VERSION ""

NS_ :

BS_:

BU_:

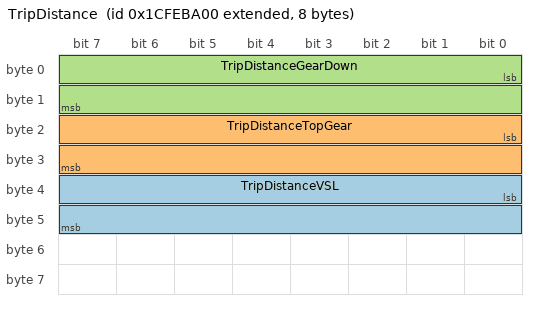
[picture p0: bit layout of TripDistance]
BO_ 2633939456 TripDistance: 8 Vector__XXX
 SG_ TripDistanceVSL : 32|16@1+ (1,0) [0|65535] "Km" Vector__XXX
 SG_ TripDistanceTopGear : 16|16@1+ (1,0) [0|65535] "Km" Vector__XXX
 SG_ TripDistanceGearDown : 0|16@1+ (1,0) [0|65535] "Km" Vector__XXX

BA_DEF_ SG_  "SigType" ENUM  "Default","Range","RangeSigned","ASCII","Discrete","Control","ReferencePGN","DTC","StringDelimiter","StringLength","StringLengthControl";
BA_DEF_ SG_  "GenSigEVName" STRING ;
BA_DEF_ SG_  "GenSigILSupport" ENUM  "Yes","No";
BA_DEF_ SG_  "GenSigSendType" ENUM  "Cyclic","OnWrite","OnWriteWithRepetition","OnChange","OnChangeWithRepetition","IfActive","IfActiveWithRepetition","NoSigSendType";
BA_DEF_ BO_  "GenMsgILSupport" ENUM  "Yes","No";
BA_DEF_ BU_  "NmStationAddress" INT 0 255;
BA_DEF_ BO_  "GenMsgSendType" ENUM  "cyclic","NotUsed","IfActive","NotUsed","NotUsed","NotUsed","NotUsed","NotUsed","noMsgSendType";
BA_DEF_ BO_  "GenMsgRequestable" INT 0 1;
BA_DEF_  "DBName" STRING ;
BA_DEF_  "BusType" STRING ;
BA_DEF_  "ProtocolType" STRING ;
BA_DEF_ BO_  "VFrameFormat" ENUM  "StandardCAN","ExtendedCAN","reserved","J1939PG";
BA_DEF_DEF_  "SigType" "Default";
BA_DEF_DEF_  "GenSigEVName" "Env@Nodename_@Signame";
BA_DEF_DEF_  "GenSigILSupport" "Yes";
BA_DEF_DEF_  "GenSigSendType" "NoSigSendType";
BA_DEF_DEF_  "GenMsgILSupport" "Yes";
BA_DEF_DEF_  "NmStationAddress" 254;
BA_DEF_DEF_  "GenMsgSendType" "noMsgSendType";
BA_DEF_DEF_  "GenMsgRequestable" 1;
BA_DEF_DEF_  "DBName" "";
BA_DEF_DEF_  "BusType" "CAN";
BA_DEF_DEF_  "ProtocolType" "J1939";
BA_DEF_DEF_  "VFrameFormat" "J1939PG";
BA_ "DBName" "sg_vehicle_test";
